# EFM32GG12B510F1024GL120 register map
File version: 4.0.0
CPU: CM4 r0p1, little endian, MPU, FPU, 3 interrupt priority bits
Registers are 32-bit, read-write, reset 0x0 unless marked. A register's access mark holds for its fields unless they carry their own. Offsets are from the block's base; [hi:lo] are bit positions; {n}, {i} and the like mark numbered series; 'fields as' and 'values as' point back to an identical list.

## RMU
Base 0x400E5000
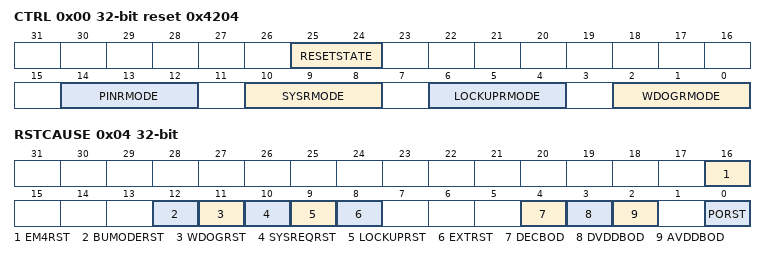
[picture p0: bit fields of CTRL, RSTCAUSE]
0x00 CTRL reset 0x4204 — Control Register
  [25:24] RESETSTATE — System Software Reset State
  [14:12] PINRMODE — PIN Reset Mode
    0=DISABLED (Reset request is blocked.); 1=LIMITED (The CRYOTIMER, DEBUGGER, RTCC, are not reset.); 2=EXTENDED (The CRYOTIMER, DEBUGGER are not reset. RTCC is reset.); 4=FULL (The entire device is reset except some EMU and RMU registers.)
  [10:8] SYSRMODE — Core Sysreset Reset Mode
    values as PINRMODE
  [6:4] LOCKUPRMODE — Core LOCKUP Reset Mode
    values as PINRMODE
  [2:0] WDOGRMODE — WDOG Reset Mode
    0=DISABLED (Reset request is blocked. This disable bit is redundant with enable/disable bit in WDOG); 1=LIMITED (The CRYOTIMER, DEBUGGER, RTCC, are not reset.); 2=EXTENDED (The CRYOTIMER, DEBUGGER are not reset. RTCC is reset.); 4=FULL (The entire device is reset except some EMU and RMU registers.)
0x04 RSTCAUSE ro — Reset Cause Register
  [16] EM4RST — EM4 Reset
  [12] BUMODERST — Backup Mode Reset
  [11] WDOGRST — Watchdog Reset
  [10] SYSREQRST — System Request Reset
  [9] LOCKUPRST — LOCKUP Reset
  [8] EXTRST — External Pin Reset
  [4] DECBOD — Brown Out Detector Decouple Domain Reset
  [3] DVDDBOD — Brown Out Detector DVDD Reset
  [2] AVDDBOD — Brown Out Detector AVDD Reset
  [0] PORST — Power on Reset
0x08 CMD wo — Command Register
  [0] RCCLR — Reset Cause Clear
0x0C RST reset not defined — Reset Control Register
0x10 LOCK — Configuration Lock Register
  [15:0] LOCKKEY — Configuration Lock Key
    0=UNLOCKED; 1=LOCKED

## PDM
Base 0x40028000
0x00 IPVERSION ro — IP Version ID
0x04 EN — PDM Module enable Register
  [0] EN — Module enable
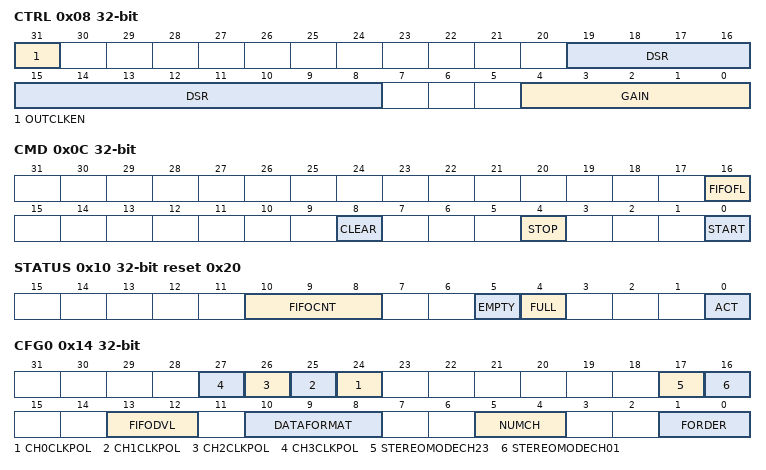
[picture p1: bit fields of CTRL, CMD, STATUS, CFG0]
0x08 CTRL — PDM Core Control Register
  [31] OUTCLKEN — PDM Clock enable
  [19:8] DSR — Down sampling rate of Decimation filter
  [4:0] GAIN — Selects Gain factor of DCF
0x0C CMD wo — PDM Core Command Register
  [16] FIFOFL — FIFO Flush
  [8] CLEAR — Clear DCF
  [4] STOP — Stop DCF
  [0] START — Start DCF
0x10 STATUS ro reset 0x20 — PDM Status register
  [10:8] FIFOCNT
  [5] EMPTY — FIFO EMPTY Status
  [4] FULL — FIFO FULL Status
  [0] ACT — PDM is active
0x14 CFG0 — PDM Core Configuration Register0
  [n+24] CH{n}CLKPOL (n=0..3) — CH{n} CLK Polarity
  [17] STEREOMODECH23
  [16] STEREOMODECH01
  [13:12] FIFODVL — Data Valid level in FIFO
    0=ONE (Atleast one word.); 1=TWO (Two words.); 2=THREE (Three words.); 3=FOUR (Four words.)
  [10:8] DATAFORMAT — Filter output format
    0=RIGHT16 (Right aligned 16-bit, left bits are sign extended.); 1=DOUBLE16 (Pack two 16-bit samples into one 32-bit word.); 2=RIGHT24 (Right aligned 24bit, left bits are sign extended.); 3=FULL32BIT (32 bit data.); 4=LEFT16 (Left aligned 16-bit, right bits are zeros.); 5=LEFT24 (Left aligned 24-bit, right bits are zeros.); 6=RAW32BIT (RAW 32 bit data from Integrator.)
  [5:4] NUMCH — Number of Channels
    0=ONE (Only one Channel.); 1=TWO (Two Channels.); 2=THREE (Three Channels.); 3=FOUR (Four Channels.)
  [1:0] FORDER — Filter order
    0=SECOND (Second order filter.); 1=THIRD (Third order filter.); 2=FOURTH (Fourth order filter.); 3=FIFTH (Fifth order filter.)
0x18 CFG1 — PDM Core Configuration Register1
  [9:0] PRESC — Prescalar Setting for PDM sample
0x20 RXDATA ro read-has-side-effects — PDM Received Data Register
  [31:0] RXDATA — PDM received data
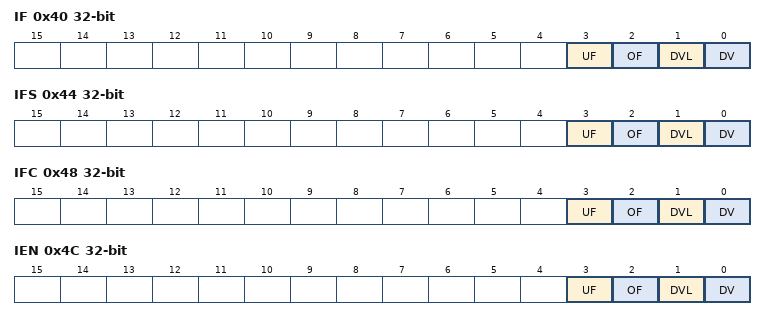
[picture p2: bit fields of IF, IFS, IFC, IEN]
0x40 IF ro — Interrupt Flag Register
  [3] UF — FIFO Undeflow Interrupt Flag
  [2] OF — FIFO Overflow Interrupt Flag
  [1] DVL — Data Valid Level Interrupt Flag
  [0] DV — Data Valid Interrupt Flag
0x44 IFS wo — Interrupt Flag Set Register
  [3] UF — Set UF Interrupt Flag
  [2] OF — Set OF Interrupt Flag
  [1] DVL — Set DVL Interrupt Flag
  [0] DV — Set DV Interrupt Flag
0x48 IFC wo — Interrupt Flag Clear Register
  [3] UF — Clear UF Interrupt Flag
  [2] OF — Clear OF Interrupt Flag
  [1] DVL — Clear DVL Interrupt Flag
  [0] DV — Clear DV Interrupt Flag
0x4C IEN — Interrupt Enable Register
  [3] UF — UF Interrupt Enable
  [2] OF — OF Interrupt Enable
  [1] DVL — DVL Interrupt Enable
  [0] DV — DV Interrupt Enable
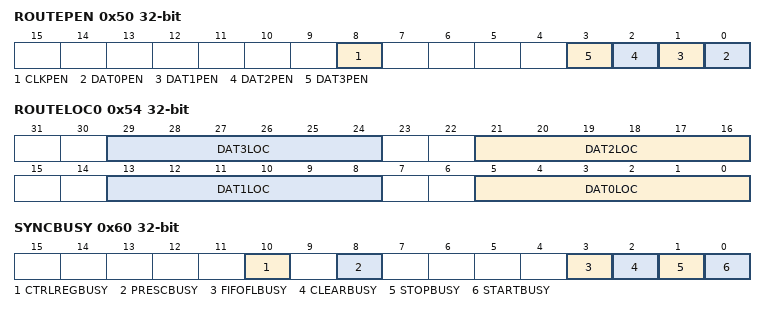
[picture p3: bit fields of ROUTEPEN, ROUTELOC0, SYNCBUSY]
0x50 ROUTEPEN — I/O LOCATION Enable Register
  [8] CLKPEN — CLK I/O Enable
  [n] DAT{n}PEN (n=0..3) — DAT{n} I/O Enable
0x54 ROUTELOC0 — I/O LOCATION Register
  [all] fields
    {v}=LOC{v} (Location {v}) (v=0..4)
  [8n+5:8n] DAT{n}LOC (n=0..3) — I/O Location for DAT{n} pins
0x58 ROUTELOC1 — I/O LOCATION Register
  [5:0] CLKLOC — I/O Location for CLK pin
    {v}=LOC{v} (Location {v}) (v=0..4)
0x60 SYNCBUSY ro — Synchronization Busy Register
  [10] CTRLREGBUSY — CTRLREGBUSY busy
  [8] PRESCBUSY — PRESC Sync busy
  [3] FIFOFLBUSY — FIFO Flush Sync busy
  [2] CLEARBUSY — CLEAR sync busy
  [1] STOPBUSY — STOP sync busy
  [0] STARTBUSY — START sync busy

## Notices in the file
# License
Copyright 2021 Silicon Laboratories Inc. www.silabs.com
SPDX-License-Identifier: Zlib
The licensor of this software is Silicon Laboratories Inc.
This software is provided 'as-is', without any express or implied
warranty. In no event will the authors be held liable for any damages
arising from the use of this software.
Permission is granted to anyone to use this software for any purpose,
including commercial applications, and to alter it and redistribute it
freely, subject to the following restrictions:
1. The origin of this software must not be misrepresented; you must not
claim that you wrote the original software. If you use this software
in a product, an acknowledgment in the product documentation would be
appreciated but is not required.
2. Altered source versions must be plainly marked as such, and must not be
misrepresented as being the original software.
3. This notice may not be removed or altered from any source distribution.
